# NUC029AN_v1 register map
File version: 1.0
Registers are 32-bit, read-write, reset 0x0 unless marked. A register's access mark holds for its fields unless they carry their own. Offsets are from the block's base; [hi:lo] are bit positions; {n}, {i} and the like mark numbered series; 'fields as' and 'values as' point back to an identical list.

## GP — GPIO Register Map
Base 0x50004000
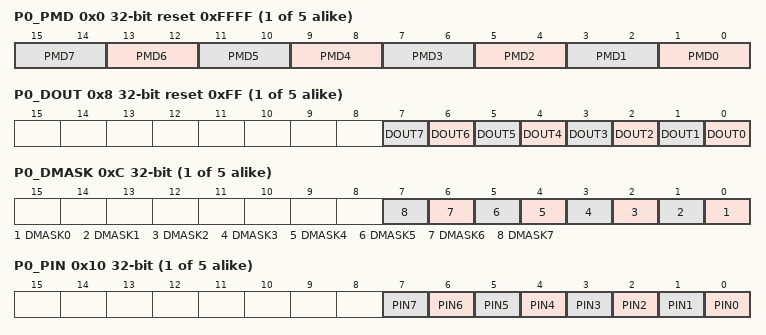
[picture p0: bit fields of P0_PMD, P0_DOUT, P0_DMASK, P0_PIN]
{0x0+0x40*i} P{i}_PMD reset 0xFFFF (i=0..4) — P{i} Pin I/O Mode Control
  [all] fields
    0=Px [n] pin is in INPUT mode; 1=Px [n] pin is in OUTPUT mode; 2=Px [n] pin is in Open-Drain mode; 3=Px [n] pin is in Quasi-bidirectional mode
  [2n+1:2n] PMD{n} (n=0..7) — Px I/O Pin[n] Mode Control. Determine each I/O type of Px pins
{0x4+0x40*i} P{i}_OFFD (i=0..4) — P{i} Digital Input Path Disable Control
  [23:16] OFFD — OFFD: Px Pin[n] Digital Input Path Disable Control
    0=Enable IO digital input path; 1=Disable IO digital input path (digital input tied to low)
{0x8+0x40*i} P{i}_DOUT reset 0xFF (i=0..4) — P{i} Data Output Value
  [all] fields
    0=Px Pin[n] will drive Low if the corresponding output mode enabling bit is set; 1=Px Pin[n] will drive High if the corresponding output mode enabling bit is set
  [n] DOUT{n} (n=0..7) — Px Pin[n] Output Value. Each of these bits control the status of a Px pin when the Px pin is configures as output, open-drain and quasi-mode.
{0xC+0x40*i} P{i}_DMASK (i=0..4) — P{i} Data Output Write Mask
  [all] fields
    0=The corresponding Px_DOUT[n] bit can be updated; 1=The corresponding Px_DOUT[n] bit is protected
  [n] DMASK{n} (n=0..7) — Px Data Output Write Mask (write-protected). These bits are used to protect the corresponding register of Px_DOUT bit[n]. When set the DMASK bit[n] to 1, the corresponding Px_DOUT[n] bit is protected. The write signal is masked, write data to the protect bit is ignored. Note: This function only protect corresponding Px_DOUT[n] bit, and will not protect corresponding bit control register (P0x_DOUT, P1x_DOUT, P2x_DOUT, P3x_DOUT, P4x_DOUT).
{0x10+0x40*i} P{i}_PIN ro (reset mask 0xFFFFFF00) (i=0..4) — P{i} Pin Value
  [n] PIN{n} (n=0..7) — Px Pin Values. The value read from each of these bit reflects the actual status of the respective Px pin
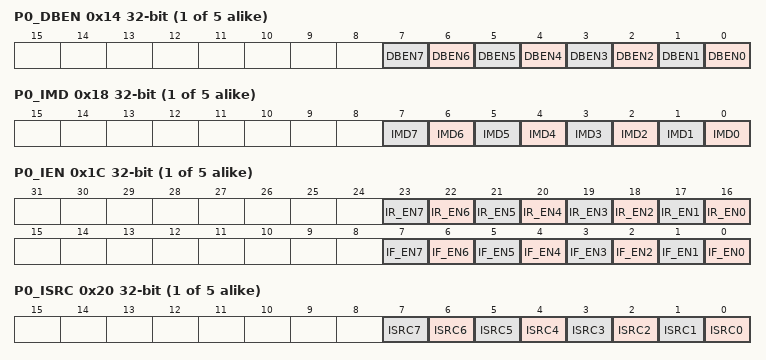
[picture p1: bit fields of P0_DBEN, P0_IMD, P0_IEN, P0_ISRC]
{0x14+0x40*i} P{i}_DBEN (i=0..4) — P{i} De-bounce Enable
  [all] fields
    0=The bit[n] de-bounce function is disabled; 1=The bit[n] de-bounce function is enabled
  [n] DBEN{n} (n=0..7) — Px Input Signal De-bounce Enable. DBEN[n]used to enable the de-bounce function for each corresponding bit. If the input signal pulse width can't be sampled by continuous two de-bounce sample cycle The input signal transition is seen as the signal bounce and will not trigger the interrupt. The DBEN[n] is used for "edge-trigger" interrupt only, and ignored for "level trigger" interrupt. Note: It is recommended setting this bit to '0' if GPIO is chosen as power down wakeup source. If set this bit to '1', will cause GPIO to produce interrupt twice. One is caused by wake up event, the other one is caused by delayed de-bounce result.
{0x18+0x40*i} P{i}_IMD (i=0..4) — P{i} Interrupt Mode Control
  [all] fields
    0=Edge trigger interrupt; 1=Level trigger interrupt
  [n] IMD{n} (n=0..7) — Port 0-4 Interrupt Mode Control. IMD[n] is used to control the interrupt is by level trigger or by edge trigger. If the interrupt is by edge trigger, the trigger source can be controlled by de-bounce. If the interrupt is by level trigger, the input source is sampled by one HCLK clock and generates the interrupt.
{0x1C+0x40*i} P{i}_IEN (i=0..4) — P{i} Interrupt Enable
  [n+16] IR_EN{n} (n=0..7) — Port 0-4 Interrupt Enable by Input Rising Edge or Input Level High. IR_EN[n] used to enable the interrupt for each of the corresponding input Px[n]. Set bit "1" also enable the pin wakeup function. When set the IR_EN[n] bit "1": If the interrupt is level mode trigger, the input Px[n] state at level "high" will generate the interrupt. If the interrupt is edge mode trigger, the input Px[n] state change from "low-to-high" will generate the interrupt.
    0=Disable the Px[n] level-high or low-to-high interrupt; 1=Enable the Px[n] level-high or low-to-high interrupt
  [n] IF_EN{n} (n=0..7) — Port 0-4 Interrupt Enable by Input Falling Edge or Input Level Low. IF_EN[n] used to enable the interrupt for each of the corresponding input Px[n]. Set bit "1" also enable the pin wakeup function. When set the IF_EB[n] bit "1": If the interrupt is level mode trigger, the input Px[n] state at level "low" will generate the interrupt. If the interrupt is edge mode trigger, the input Px[n] state change from "high-to-low" will generate the interrupt.
    0=Disable the Px[n] state low-level or high-to-low change interrupt; 1=Enable the Px[n] state low-level or high-to-low change interrupt
{0x20+0x40*i} P{i}_ISRC (i=0..4) — P{i} Interrupt Source Flag
  [all] fields
    0=No interrupt at Px[n]. No action; 1=Indicates Px[n] generate an interrupt. Clear the correspond pending interrupt
  [n] ISRC{n} (n=0..7) — Port 0-4 Interrupt Source Flag. Read :
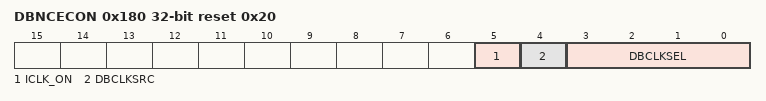
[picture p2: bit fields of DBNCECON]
0x180 DBNCECON reset 0x20 — External Interrupt De-bounce Control
  [5] ICLK_ON — Interru. It is recommended to turn off this bit to save system power, if on special application concern.
    0=Edge detection circuit is active only if IO pin corresponding GPIOx_IEN bit is set to 1; 1=All IO pins edge detection circuit is always active after reset
  [4] DBCLKSRC — De-bounce counter clock source select
    0=De-bounce counter clock source is the HCLK; 1=De-bounce counter clock source is the internal 10kHz clock
  [3:0] DBCLKSEL — De-bounce sampling cycle selection
0x200 P00_PDIO (reset mask 0xFFFFFFF0) — GPIO P0.0 Pin Data Input/Output
  [0] Pxn_PDIO — GPIO Px.n Pin Data Input/Output. Write this bit can control one GPIO pin output value
    0=Set corresponding GPIO pin to low; 1=Set corresponding GPIO pin to high
0x204 P01_PDIO (reset mask 0xFFFFFFF0) — GPIO P0.1 Pin Data Input/Output
  fields as P00_PDIO
0x208 P02_PDIO (reset mask 0xFFFFFFF0) — GPIO P0.2 Pin Data Input/Output
  fields as P00_PDIO
0x20C P03_PDIO (reset mask 0xFFFFFFF0) — GPIO P0.3 Pin Data Input/Output
  fields as P00_PDIO
0x210 P04_PDIO (reset mask 0xFFFFFFF0) — GPIO P0.4 Pin Data Input/Output
  fields as P00_PDIO
0x214 P05_PDIO (reset mask 0xFFFFFFF0) — GPIO P0.5 Pin Data Input/Output
  fields as P00_PDIO
0x218 P06_PDIO (reset mask 0xFFFFFFF0) — GPIO P0.6 Pin Data Input/Output
  fields as P00_PDIO
0x21C P07_PDIO (reset mask 0xFFFFFFF0) — GPIO P0.7 Pin Data Input/Output
  fields as P00_PDIO
0x220 P10_PDIO (reset mask 0xFFFFFFF0) — GPIO P1.0 Pin Data Input/Output
  fields as P00_PDIO
0x224 P11_PDIO (reset mask 0xFFFFFFF0) — GPIO P1.1 Pin Data Input/Output
  fields as P00_PDIO
0x228 P12_PDIO (reset mask 0xFFFFFFF0) — GPIO P1.2 Pin Data Input/Output
  fields as P00_PDIO
0x22C P13_PDIO (reset mask 0xFFFFFFF0) — GPIO P1.3 Pin Data Input/Output
  fields as P00_PDIO
0x230 P14_PDIO (reset mask 0xFFFFFFF0) — GPIO P1.4 Pin Data Input/Output
  fields as P00_PDIO
0x234 P15_PDIO (reset mask 0xFFFFFFF0) — GPIO P1.5 Pin Data Input/Output
  fields as P00_PDIO
0x238 P16_PDIO (reset mask 0xFFFFFFF0) — GPIO P1.6 Pin Data Input/Output
  fields as P00_PDIO
0x23C P17_PDIO (reset mask 0xFFFFFFF0) — GPIO P1.7 Pin Data Input/Output
  fields as P00_PDIO
0x240 P20_PDIO (reset mask 0xFFFFFFF0) — GPIO P2.0 Pin Data Input/Output
  fields as P00_PDIO
0x244 P21_PDIO (reset mask 0xFFFFFFF0) — GPIO P2.1 Pin Data Input/Output
  fields as P00_PDIO
0x248 P22_PDIO (reset mask 0xFFFFFFF0) — GPIO P2.2 Pin Data Input/Output
  fields as P00_PDIO
0x24C P23_PDIO (reset mask 0xFFFFFFF0) — GPIO P2.3 Pin Data Input/Output
  fields as P00_PDIO
0x250 P24_PDIO (reset mask 0xFFFFFFF0) — GPIO P2.4 Pin Data Input/Output
  fields as P00_PDIO
0x254 P25_PDIO (reset mask 0xFFFFFFF0) — GPIO P2.5 Pin Data Input/Output
  fields as P00_PDIO
0x258 P26_PDIO (reset mask 0xFFFFFFF0) — GPIO P2.6 Pin Data Input/Output
  fields as P00_PDIO
0x25C P27_PDIO (reset mask 0xFFFFFFF0) — GPIO P2.7 Pin Data Input/Output
  fields as P00_PDIO
0x260 P30_PDIO (reset mask 0xFFFFFFF0) — GPIO P3.0 Pin Data Input/Output
  fields as P00_PDIO
0x264 P31_PDIO (reset mask 0xFFFFFFF0) — GPIO P3.1 Pin Data Input/Output
  fields as P00_PDIO
0x268 P32_PDIO (reset mask 0xFFFFFFF0) — GPIO P3.2 Pin Data Input/Output
  fields as P00_PDIO
0x26C P33_PDIO (reset mask 0xFFFFFFF0) — GPIO P3.3 Pin Data Input/Output
  fields as P00_PDIO
0x270 P34_PDIO (reset mask 0xFFFFFFF0) — GPIO P3.4 Pin Data Input/Output
  fields as P00_PDIO
0x274 P35_PDIO (reset mask 0xFFFFFFF0) — GPIO P3.5 Pin Data Input/Output
  fields as P00_PDIO
0x278 P36_PDIO (reset mask 0xFFFFFFF0) — GPIO P3.6 Pin Data Input/Output
  fields as P00_PDIO
0x27C P37_PDIO (reset mask 0xFFFFFFF0) — GPIO P3.7 Pin Data Input/Output
  fields as P00_PDIO
0x280 P40_PDIO (reset mask 0xFFFFFFF0) — GPIO P4.0 Pin Data Input/Output
  fields as P00_PDIO
0x284 P41_PDIO (reset mask 0xFFFFFFF0) — GPIO P4.1 Pin Data Input/Output
  fields as P00_PDIO
0x288 P42_PDIO (reset mask 0xFFFFFFF0) — GPIO P4.2 Pin Data Input/Output
  fields as P00_PDIO
0x28C P43_PDIO (reset mask 0xFFFFFFF0) — GPIO P4.3 Pin Data Input/Output
  fields as P00_PDIO
0x290 P44_PDIO (reset mask 0xFFFFFFF0) — GPIO P4.4 Pin Data Input/Output
  fields as P00_PDIO
0x294 P45_PDIO (reset mask 0xFFFFFFF0) — GPIO P4.5 Pin Data Input/Output
  fields as P00_PDIO
0x298 P46_PDIO (reset mask 0xFFFFFFF0) — GPIO P4.6 Pin Data Input/Output
  fields as P00_PDIO
0x29C P47_PDIO (reset mask 0xFFFFFFF0) — GPIO P4.7 Pin Data Input/Output
  fields as P00_PDIO
